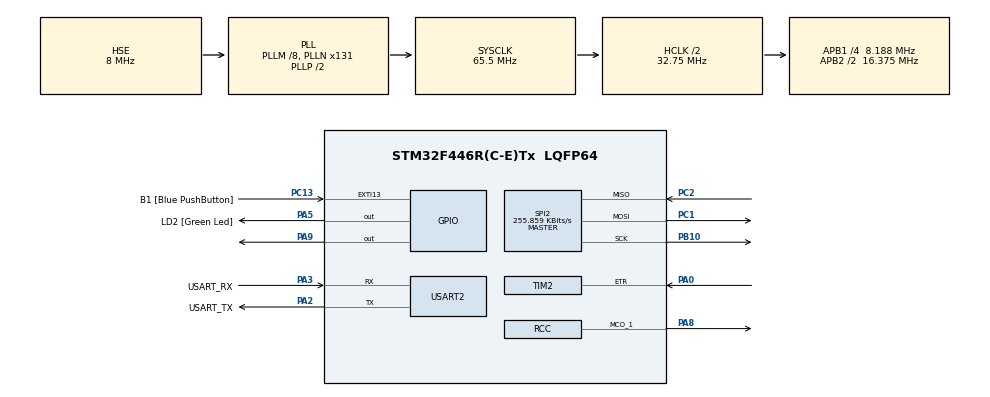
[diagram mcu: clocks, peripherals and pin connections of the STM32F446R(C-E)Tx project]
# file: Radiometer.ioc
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Mcu.Family=STM32F4
Mcu.Name=STM32F446R(C-E)Tx
Mcu.Package=LQFP64
NVIC.PriorityGroup=NVIC_PRIORITYGROUP_0
PA0-WKUP.Signal=S_TIM2_CH1_ETR
PA13.GPIO_Label=TMS
PA13.Mode=Serial_Wire
PA13.Signal=SYS_JTMS-SWDIO
PA14.GPIO_Label=TCK
PA14.Mode=Serial_Wire
PA14.Signal=SYS_JTCK-SWCLK
PA2.GPIO_Label=USART_TX
PA2.Mode=Asynchronous
PA2.Signal=USART2_TX
PA3.GPIO_Label=USART_RX
PA3.Mode=Asynchronous
PA3.Signal=USART2_RX
PA5.GPIO_Label=LD2 [Green Led]
PA5.Signal=GPIO_Output
PA8.Mode=Clock-out-1
PA8.Signal=RCC_MCO_1
PA9.GPIO_Speed=GPIO_SPEED_FREQ_HIGH
PA9.PinState=GPIO_PIN_RESET
PA9.Signal=GPIO_Output
PB10.Mode=Full_Duplex_Master
PB10.Signal=SPI2_SCK
PB3.GPIO_Label=SWO
PB3.Signal=SYS_JTDO-SWO
PC1.Mode=Full_Duplex_Master
PC1.Signal=SPI2_MOSI
PC13.GPIO_Label=B1 [Blue PushButton]
PC13.GPIO_ModeDefaultEXTI=GPIO_MODE_IT_FALLING
PC13.Signal=GPXTI13
PC14-OSC32_IN.Mode=LSE-External-Oscillator
PC14-OSC32_IN.Signal=RCC_OSC32_IN
PC15-OSC32_OUT.Mode=LSE-External-Oscillator
PC15-OSC32_OUT.Signal=RCC_OSC32_OUT
PC2.Mode=Full_Duplex_Master
PC2.Signal=SPI2_MISO
PH0-OSC_IN.Mode=HSE-External-Oscillator
PH0-OSC_IN.Signal=RCC_OSC_IN
PH1-OSC_OUT.Mode=HSE-External-Oscillator
PH1-OSC_OUT.Signal=RCC_OSC_OUT
ProjectManager.HeapSize=0x200
ProjectManager.StackSize=0x400
ProjectManager.TargetToolchain=STM32CubeIDE
RCC.48MHZClocksFreq_Value=84000000
RCC.AHBCLKDivider=RCC_SYSCLK_DIV2
RCC.AHBFreq_Value=32750000
RCC.APB1CLKDivider=RCC_HCLK_DIV4
RCC.APB1Freq_Value=8187500
RCC.APB1TimFreq_Value=16375000
RCC.APB2CLKDivider=RCC_HCLK_DIV2
RCC.APB2Freq_Value=16375000
RCC.APB2TimFreq_Value=32750000
RCC.CortexFreq_Value=32750000
RCC.FLatency-AdvancedSettings=FLASH_LATENCY_1
RCC.HCLKFreq_Value=32750000
RCC.HSE_VALUE=8000000
RCC.HSI_VALUE=16000000
RCC.PLLM=8
RCC.PLLN=131
RCC.PLLSourceVirtual=RCC_PLLSOURCE_HSE
RCC.RCC_MCO1Source=RCC_MCO1SOURCE_PLLCLK
RCC.RCC_MCODiv1=RCC_MCODIV_4
RCC.SYSCLKFreq_VALUE=65500000
RCC.SYSCLKSource=RCC_SYSCLKSOURCE_PLLCLK
RCC.USBFreq_Value=65500000
RCC.VCOOutputFreq_Value=131000000
SH.S_TIM2_CH1_ETR.0=TIM2_ETR,ClockSourceETR_Mode2
SPI2.BaudRatePrescaler=SPI_BAUDRATEPRESCALER_32
SPI2.CalculateBaudRate=255.859 KBits/s
SPI2.Direction=SPI_DIRECTION_2LINES
SPI2.Mode=SPI_MODE_MASTER
SPI2.VirtualType=VM_MASTER
USART2.VirtualMode=VM_ASYNC
board=NUCLEO-F446RE

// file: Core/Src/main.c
/* USER CODE BEGIN Header */
/**
  ******************************************************************************
  * @file           : main.c
  * @brief          : Main program body
  ******************************************************************************
  * @attention
  *
  * <h2><center>&copy; Copyright (c) 2020 STMicroelectronics.
  * All rights reserved.</center></h2>
  *
  * This software component is licensed by ST under BSD 3-Clause license,
  * the "License"; You may not use this file except in compliance with the
  * License. You may obtain a copy of the License at:
  *                        opensource.org/licenses/BSD-3-Clause
  *
  ******************************************************************************
  */
/* USER CODE END Header */

#include "main.h"

SPI_HandleTypeDef hspi2;

TIM_HandleTypeDef htim2;

UART_HandleTypeDef huart2;

void SystemClock_Config(void);
static void MX_GPIO_Init(void);
static void MX_USART2_UART_Init(void);
static void MX_SPI2_Init(void);
static void MX_TIM2_Init(void);

int main(void)
{

  /* MCU Configuration--------------------------------------------------------*/

  /* Reset of all peripherals, Initializes the Flash interface and the Systick. */
  HAL_Init();

  /* Configure the system clock */
  SystemClock_Config();

  /* Initialize all configured peripherals */
  MX_GPIO_Init();
  MX_USART2_UART_Init();
  MX_SPI2_Init();
  MX_TIM2_Init();
  /* USER CODE BEGIN 2 */
  //HAL_GPIO_WritePin(GPIOA, GPIO_Pin_9, GPIO_PIN_SET);
  HAL_Delay(10);

  /* USER CODE END 2 */

  /* Infinite loop */
  while (1)
  {

    /* USER CODE BEGIN 3 */
	  HAL_GPIO_ReadPin(GPIOA, GPIO_PIN_2);
	  mco_config();
  }
  /* USER CODE END 3 */
}

void SystemClock_Config(void)
{
  RCC_OscInitTypeDef RCC_OscInitStruct = {0};
  RCC_ClkInitTypeDef RCC_ClkInitStruct = {0};

  /** Configure the main internal regulator output voltage
  */
  __HAL_RCC_PWR_CLK_ENABLE();
  __HAL_PWR_VOLTAGESCALING_CONFIG(PWR_REGULATOR_VOLTAGE_SCALE3);
  /** Initializes the CPU, AHB and APB busses clocks
  */
  RCC_OscInitStruct.OscillatorType = RCC_OSCILLATORTYPE_HSE;
  RCC_OscInitStruct.HSEState = RCC_HSE_ON;
  RCC_OscInitStruct.PLL.PLLState = RCC_PLL_ON;
  RCC_OscInitStruct.PLL.PLLSource = RCC_PLLSOURCE_HSE;
  RCC_OscInitStruct.PLL.PLLM = 8;
  RCC_OscInitStruct.PLL.PLLN = 131;
  RCC_OscInitStruct.PLL.PLLP = RCC_PLLP_DIV2;
  RCC_OscInitStruct.PLL.PLLQ = 2;
  RCC_OscInitStruct.PLL.PLLR = 2;
  if (HAL_RCC_OscConfig(&RCC_OscInitStruct) != HAL_OK)
  {
    Error_Handler();
  }
  /** Initializes the CPU, AHB and APB busses clocks
  */
  RCC_ClkInitStruct.ClockType = RCC_CLOCKTYPE_HCLK|RCC_CLOCKTYPE_SYSCLK
                              |RCC_CLOCKTYPE_PCLK1|RCC_CLOCKTYPE_PCLK2;
  RCC_ClkInitStruct.SYSCLKSource = RCC_SYSCLKSOURCE_PLLCLK;
  RCC_ClkInitStruct.AHBCLKDivider = RCC_SYSCLK_DIV2;
  RCC_ClkInitStruct.APB1CLKDivider = RCC_HCLK_DIV4;
  RCC_ClkInitStruct.APB2CLKDivider = RCC_HCLK_DIV2;

  if (HAL_RCC_ClockConfig(&RCC_ClkInitStruct, FLASH_LATENCY_1) != HAL_OK)
  {
    Error_Handler();
  }
  HAL_RCC_MCOConfig(RCC_MCO1, RCC_MCO1SOURCE_PLLCLK, RCC_MCODIV_4);
}

static void MX_SPI2_Init(void)
{

  /* SPI2 parameter configuration*/
  hspi2.Instance = SPI2;
  hspi2.Init.Mode = SPI_MODE_MASTER;
  hspi2.Init.Direction = SPI_DIRECTION_2LINES;
  hspi2.Init.DataSize = SPI_DATASIZE_8BIT;
  hspi2.Init.CLKPolarity = SPI_POLARITY_LOW;
  hspi2.Init.CLKPhase = SPI_PHASE_1EDGE;
  hspi2.Init.NSS = SPI_NSS_SOFT;
  hspi2.Init.BaudRatePrescaler = SPI_BAUDRATEPRESCALER_32;
  hspi2.Init.FirstBit = SPI_FIRSTBIT_MSB;
  hspi2.Init.TIMode = SPI_TIMODE_DISABLE;
  hspi2.Init.CRCCalculation = SPI_CRCCALCULATION_DISABLE;
  hspi2.Init.CRCPolynomial = 10;
  if (HAL_SPI_Init(&hspi2) != HAL_OK)
  {
    Error_Handler();
  }

}

static void MX_TIM2_Init(void)
{

  TIM_ClockConfigTypeDef sClockSourceConfig = {0};
  TIM_MasterConfigTypeDef sMasterConfig = {0};

  htim2.Instance = TIM2;
  htim2.Init.Prescaler = 0;
  htim2.Init.CounterMode = TIM_COUNTERMODE_UP;
  htim2.Init.Period = 0;
  htim2.Init.ClockDivision = TIM_CLOCKDIVISION_DIV1;
  htim2.Init.AutoReloadPreload = TIM_AUTORELOAD_PRELOAD_DISABLE;
  if (HAL_TIM_Base_Init(&htim2) != HAL_OK)
  {
    Error_Handler();
  }
  sClockSourceConfig.ClockSource = TIM_CLOCKSOURCE_ETRMODE2;
  sClockSourceConfig.ClockPolarity = TIM_CLOCKPOLARITY_NONINVERTED;
  sClockSourceConfig.ClockPrescaler = TIM_CLOCKPRESCALER_DIV1;
  sClockSourceConfig.ClockFilter = 0;
  if (HAL_TIM_ConfigClockSource(&htim2, &sClockSourceConfig) != HAL_OK)
  {
    Error_Handler();
  }
  sMasterConfig.MasterOutputTrigger = TIM_TRGO_RESET;
  sMasterConfig.MasterSlaveMode = TIM_MASTERSLAVEMODE_DISABLE;
  if (HAL_TIMEx_MasterConfigSynchronization(&htim2, &sMasterConfig) != HAL_OK)
  {
    Error_Handler();
  }

}

static void MX_USART2_UART_Init(void)
{

  huart2.Instance = USART2;
  huart2.Init.BaudRate = 115200;
  huart2.Init.WordLength = UART_WORDLENGTH_8B;
  huart2.Init.StopBits = UART_STOPBITS_1;
  huart2.Init.Parity = UART_PARITY_NONE;
  huart2.Init.Mode = UART_MODE_TX_RX;
  huart2.Init.HwFlowCtl = UART_HWCONTROL_NONE;
  huart2.Init.OverSampling = UART_OVERSAMPLING_16;
  if (HAL_UART_Init(&huart2) != HAL_OK)
  {
    Error_Handler();
  }

}

static void MX_GPIO_Init(void)
{
  GPIO_InitTypeDef GPIO_InitStruct = {0};

  /* GPIO Ports Clock Enable */
  __HAL_RCC_GPIOC_CLK_ENABLE();
  __HAL_RCC_GPIOH_CLK_ENABLE();
  __HAL_RCC_GPIOA_CLK_ENABLE();
  __HAL_RCC_GPIOB_CLK_ENABLE();

  /*Configure GPIO pin Output Level */
  HAL_GPIO_WritePin(GPIOA, LD2_Pin|GPIO_PIN_9, GPIO_PIN_RESET);

  /*Configure GPIO pin : B1_Pin */
  GPIO_InitStruct.Pin = B1_Pin;
  GPIO_InitStruct.Mode = GPIO_MODE_IT_FALLING;
  GPIO_InitStruct.Pull = GPIO_NOPULL;
  HAL_GPIO_Init(B1_GPIO_Port, &GPIO_InitStruct);

  /*Configure GPIO pin : LD2_Pin */
  GPIO_InitStruct.Pin = LD2_Pin;
  GPIO_InitStruct.Mode = GPIO_MODE_OUTPUT_PP;
  GPIO_InitStruct.Pull = GPIO_NOPULL;
  GPIO_InitStruct.Speed = GPIO_SPEED_FREQ_LOW;
  HAL_GPIO_Init(LD2_GPIO_Port, &GPIO_InitStruct);

  /*Configure GPIO pin : PA8 */
  GPIO_InitStruct.Pin = GPIO_PIN_8;
  GPIO_InitStruct.Mode = GPIO_MODE_AF_PP;
  GPIO_InitStruct.Pull = GPIO_NOPULL;
  GPIO_InitStruct.Speed = GPIO_SPEED_FREQ_LOW;
  GPIO_InitStruct.Alternate = GPIO_AF0_MCO;
  HAL_GPIO_Init(GPIOA, &GPIO_InitStruct);

  /*Configure GPIO pin : PA9 */
  GPIO_InitStruct.Pin = GPIO_PIN_9;
  GPIO_InitStruct.Mode = GPIO_MODE_OUTPUT_PP;
  GPIO_InitStruct.Pull = GPIO_NOPULL;
  GPIO_InitStruct.Speed = GPIO_SPEED_FREQ_HIGH;
  HAL_GPIO_Init(GPIOA, &GPIO_InitStruct);

}

/* USER CODE BEGIN 4 */
void mco_config()
{
	RCC->AHB1ENR |= RCC_AHB1ENR_GPIOAEN;
	GPIOA->MODER |= GPIO_MODER_MODER8_1;

	RCC->CFGR |=RCC_CFGR_PPRE1_DIV4;
	//RCC->CFGR |= RCC_CFGR_MCO1_1;
	//RCC->CFGR &= ~RCC_CFGR_MCO1PRE;
	//RCC->CFGR = (RCC->CFGR AND (~(RCC_CFGR_SW)));
	RCC->CFGR |= 0;
	}

/* USER CODE END 4 */

void Error_Handler(void)
{
}

/************************ (C) COPYRIGHT STMicroelectronics *****END OF FILE****/
